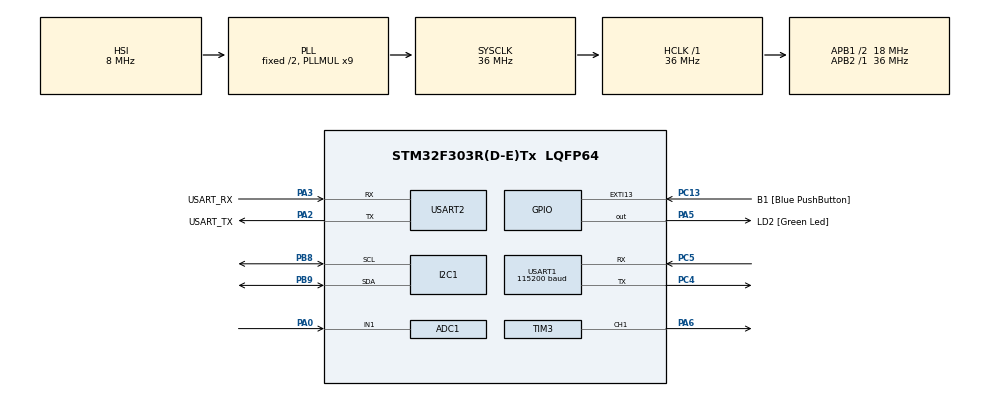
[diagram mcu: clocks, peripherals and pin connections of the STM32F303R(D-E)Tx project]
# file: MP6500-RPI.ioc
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ADC1.Channel-0\#ChannelRegularConversion=ADC_CHANNEL_1
ADC1.ContinuousConvMode=ENABLE
ADC1.DMAContinuousRequests=ENABLE
ADC1.NbrOfConversion=1
ADC1.NbrOfConversionFlag=1
ADC1.Offset-0\#ChannelRegularConversion=0
ADC1.OffsetNumber-0\#ChannelRegularConversion=ADC_OFFSET_NONE
ADC1.Rank-0\#ChannelRegularConversion=1
ADC1.SamplingTime-0\#ChannelRegularConversion=ADC_SAMPLETIME_61CYCLES_5
ADC1.SamplingTimeOPAMP-0\#ChannelRegularConversion=ADC_SAMPLETIME_19CYCLES_5
ADC1.master=1
Dma.ADC1.0.Direction=DMA_PERIPH_TO_MEMORY
Dma.ADC1.0.Instance=DMA1_Channel1
Dma.ADC1.0.MemDataAlignment=DMA_MDATAALIGN_HALFWORD
Dma.ADC1.0.MemInc=DMA_MINC_ENABLE
Dma.ADC1.0.Mode=DMA_CIRCULAR
Dma.ADC1.0.PeriphDataAlignment=DMA_PDATAALIGN_HALFWORD
Dma.ADC1.0.PeriphInc=DMA_PINC_DISABLE
Dma.ADC1.0.Priority=DMA_PRIORITY_LOW
Dma.Request0=ADC1
FREERTOS.Mutexes01=uartMutex,Dynamic,NULL,Available
FREERTOS.Queues01=sensorDataQueu,16,6,1,Dynamic,NULL,NULL
FREERTOS.Tasks01=defaultTask,24,128,StartDefaultTask,Default,NULL,Dynamic,NULL,NULL;Task_ReadSensor,24,128,StartTask_ReadSensor,Default,NULL,Dynamic,NULL,NULL;TaskSendMAVLINK,24,512,StartTask_SendMAVLINK,Default,NULL,Dynamic,NULL,NULL;Task_Heartbeat,24,512,StartTaskHeartbeat,Default,NULL,Dynamic,NULL,NULL;Task_Servo,24,128,StartTask_Servo,Default,NULL,Dynamic,NULL,NULL
FREERTOS.configTOTAL_HEAP_SIZE=16384
I2C1.Timing=0x00201D2B
Mcu.Family=STM32F3
Mcu.Name=STM32F303R(D-E)Tx
Mcu.Package=LQFP64
NVIC.DMA1_Channel1_IRQn=true\:0\:0\:false\:false\:true\:false\:false\:true\:true
NVIC.PriorityGroup=NVIC_PRIORITYGROUP_4
NVIC.TIM6_DAC_IRQn=true\:15\:0\:false\:false\:true\:false\:false\:true\:true
NVIC.TimeBase=TIM6_DAC_IRQn
NVIC.TimeBaseIP=TIM6
PA0.Mode=IN1-Single-Ended
PA0.Signal=ADC1_IN1
PA13.GPIO_Label=TMS
PA13.Mode=Serial_Wire
PA13.Signal=SYS_JTMS-SWDIO
PA14.GPIO_Label=TCK
PA14.Mode=Serial_Wire
PA14.Signal=SYS_JTCK-SWCLK
PA2.GPIO_Label=USART_TX
PA2.GPIO_Mode=GPIO_MODE_AF_PP
PA2.GPIO_PuPd=GPIO_NOPULL
PA2.GPIO_Speed=GPIO_SPEED_FREQ_LOW
PA2.Mode=Asynchronous
PA2.Signal=USART2_TX
PA3.GPIO_Label=USART_RX
PA3.GPIO_Mode=GPIO_MODE_AF_PP
PA3.GPIO_PuPd=GPIO_NOPULL
PA3.GPIO_Speed=GPIO_SPEED_FREQ_LOW
PA3.Mode=Asynchronous
PA3.Signal=USART2_RX
PA5.GPIO_Label=LD2 [Green Led]
PA5.GPIO_Mode=GPIO_MODE_OUTPUT_PP
PA5.GPIO_PuPd=GPIO_NOPULL
PA5.GPIO_Speed=GPIO_SPEED_FREQ_LOW
PA5.Signal=GPIO_Output
PA6.Signal=S_TIM3_CH1
PB3.GPIO_Label=SWO
PB3.Signal=SYS_JTDO-TRACESWO
PB8.Mode=I2C
PB8.Signal=I2C1_SCL
PB9.Mode=I2C
PB9.Signal=I2C1_SDA
PC13.GPIO_Label=B1 [Blue PushButton]
PC13.GPIO_ModeDefaultEXTI=GPIO_MODE_IT_FALLING
PC13.Signal=GPXTI13
PC14-OSC32_IN.Mode=LSE-External-Oscillator
PC14-OSC32_IN.Signal=RCC_OSC32_IN
PC15-OSC32_OUT.Mode=LSE-External-Oscillator
PC15-OSC32_OUT.Signal=RCC_OSC32_OUT
PC4.Mode=Asynchronous
PC4.Signal=USART1_TX
PC5.Mode=Asynchronous
PC5.Signal=USART1_RX
PF0-OSC_IN.Mode=HSE-External-Clock-Source
PF0-OSC_IN.Signal=RCC_OSC_IN
PF1-OSC_OUT.Signal=RCC_OSC_OUT
ProjectManager.HeapSize=0x200
ProjectManager.StackSize=0x400
ProjectManager.TargetToolchain=STM32CubeIDE
RCC.AHBFreq_Value=36000000
RCC.APB1CLKDivider=RCC_HCLK_DIV2
RCC.APB1Freq_Value=18000000
RCC.APB1TimFreq_Value=36000000
RCC.APB2Freq_Value=36000000
RCC.APB2TimFreq_Value=36000000
RCC.CortexFreq_Value=36000000
RCC.HCLKFreq_Value=36000000
RCC.HSE_VALUE=8000000
RCC.HSI_VALUE=8000000
RCC.PLLM=8
RCC.PLLMUL=RCC_PLL_MUL9
RCC.PLLN=336
RCC.PLLP=RCC_PLLP_DIV4
RCC.PLLQ=7
RCC.RCC_PLLsource_Clock_Source_FROM_HSE=RCC_HSE_PREDIV_DIV2
RCC.SYSCLKFreq_VALUE=36000000
RCC.SYSCLKSourceVirtual=RCC_SYSCLKSOURCE_PLLCLK
RCC.USBFreq_Value=36000000
SH.S_TIM3_CH1.0=TIM3_CH1,PWM Generation1 CH1
TIM3.Channel-PWM\ Generation1\ CH1=TIM_CHANNEL_1
TIM3.Period=19999
TIM3.Prescaler=35
TIM3.Pulse-PWM\ Generation1\ CH1=1500
USART1.BaudRate=115200
USART1.VirtualMode-Asynchronous=VM_ASYNC
USART2.VirtualMode-Asynchronous=VM_ASYNC
VP_FREERTOS_VS_CMSIS_V2.Mode=CMSIS_V2
VP_SYS_VS_tim6.Mode=TIM6
board=NUCLEO-F303RE

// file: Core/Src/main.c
/* USER CODE BEGIN Header */
/**
  ******************************************************************************
  * @file           : main.c
  * @brief          : Main program body
  ******************************************************************************
  * @attention
  *
  * Copyright (c) 2026 STMicroelectronics.
  * All rights reserved.
  *
  * This software is licensed under terms that can be found in the LICENSE file
  * in the root directory of this software component.
  * If no LICENSE file comes with this software, it is provided AS-IS.
  *
  ******************************************************************************
  */
/* USER CODE END Header */
#include "main.h"
#include "cmsis_os.h"

/* USER CODE BEGIN Includes */
#include "servo.h"
#include "mpu6500.h"
#include "tasks.h"
/* USER CODE END Includes */

ADC_HandleTypeDef hadc1;
DMA_HandleTypeDef hdma_adc1;

I2C_HandleTypeDef hi2c1;

TIM_HandleTypeDef htim3;

UART_HandleTypeDef huart1;
UART_HandleTypeDef huart2;

/* Definitions for defaultTask */
osThreadId_t defaultTaskHandle;
const osThreadAttr_t defaultTask_attributes = {
  .name = "defaultTask",
  .stack_size = 128 * 4,
  .priority = (osPriority_t) osPriorityNormal,
};
/* Definitions for Task_ReadSensor */
osThreadId_t Task_ReadSensorHandle;
const osThreadAttr_t Task_ReadSensor_attributes = {
  .name = "Task_ReadSensor",
  .stack_size = 128 * 4,
  .priority = (osPriority_t) osPriorityNormal,
};
/* Definitions for TaskSendMAVLINK */
osThreadId_t TaskSendMAVLINKHandle;
const osThreadAttr_t TaskSendMAVLINK_attributes = {
  .name = "TaskSendMAVLINK",
  .stack_size = 512 * 4,
  .priority = (osPriority_t) osPriorityNormal,
};
/* Definitions for Task_Heartbeat */
osThreadId_t Task_HeartbeatHandle;
const osThreadAttr_t Task_Heartbeat_attributes = {
  .name = "Task_Heartbeat",
  .stack_size = 512 * 4,
  .priority = (osPriority_t) osPriorityNormal,
};
/* Definitions for Task_Servo */
osThreadId_t Task_ServoHandle;
const osThreadAttr_t Task_Servo_attributes = {
  .name = "Task_Servo",
  .stack_size = 128 * 4,
  .priority = (osPriority_t) osPriorityNormal,
};
/* Definitions for sensorDataQueu */
osMessageQueueId_t sensorDataQueuHandle;
const osMessageQueueAttr_t sensorDataQueu_attributes = {
  .name = "sensorDataQueu"
};
/* Definitions for uartMutex */
osMutexId_t uartMutexHandle;
const osMutexAttr_t uartMutex_attributes = {
  .name = "uartMutex"
};
/* USER CODE BEGIN PV */
volatile uint16_t adc_raw;
/* USER CODE END PV */

void SystemClock_Config(void);
static void MX_GPIO_Init(void);
static void MX_DMA_Init(void);
static void MX_USART2_UART_Init(void);
static void MX_I2C1_Init(void);
static void MX_USART1_UART_Init(void);
static void MX_TIM3_Init(void);
static void MX_ADC1_Init(void);
void StartDefaultTask(void *argument);
void StartTask_ReadSensor(void *argument);
void StartTask_SendMAVLINK(void *argument);
void StartTaskHeartbeat(void *argument);
void StartTask_Servo(void *argument);

int main(void)
{

  /* MCU Configuration--------------------------------------------------------*/

  /* Reset of all peripherals, Initializes the Flash interface and the Systick. */
  HAL_Init();

  /* Configure the system clock */
  SystemClock_Config();

  /* Initialize all configured peripherals */
  MX_GPIO_Init();
  MX_DMA_Init();
  MX_USART2_UART_Init();
  MX_I2C1_Init();
  MX_USART1_UART_Init();
  MX_TIM3_Init();
  MX_ADC1_Init();
  /* USER CODE BEGIN 2 */
  if (MPU6500_Init() != 0) { Error_Handler(); }
  Servo_init();
  HAL_ADCEx_Calibration_Start(&hadc1, ADC_SINGLE_ENDED);
  HAL_ADC_Start_DMA(&hadc1, (uint32_t*)&adc_raw, 1);
  HAL_NVIC_DisableIRQ(DMA1_Channel1_IRQn);
  /* USER CODE END 2 */

  /* Init scheduler */
  osKernelInitialize();
  /* Create the mutex(es) */
  /* creation of uartMutex */
  uartMutexHandle = osMutexNew(&uartMutex_attributes);

  /* Create the queue(s) */
  /* creation of sensorDataQueu */
  sensorDataQueuHandle = osMessageQueueNew (16, 6, &sensorDataQueu_attributes);

  /* Create the thread(s) */
  /* creation of defaultTask */
  defaultTaskHandle = osThreadNew(StartDefaultTask, NULL, &defaultTask_attributes);

  /* creation of Task_ReadSensor */
  Task_ReadSensorHandle = osThreadNew(StartTask_ReadSensor, NULL, &Task_ReadSensor_attributes);

  /* creation of TaskSendMAVLINK */
  TaskSendMAVLINKHandle = osThreadNew(StartTask_SendMAVLINK, NULL, &TaskSendMAVLINK_attributes);

  /* creation of Task_Heartbeat */
  Task_HeartbeatHandle = osThreadNew(StartTaskHeartbeat, NULL, &Task_Heartbeat_attributes);

  /* creation of Task_Servo */
  Task_ServoHandle = osThreadNew(StartTask_Servo, NULL, &Task_Servo_attributes);

  /* Start scheduler */
  osKernelStart();

  /* We should never get here as control is now taken by the scheduler */

  /* Infinite loop */
  while (1)
  {

  }
}

void SystemClock_Config(void)
{
  RCC_OscInitTypeDef RCC_OscInitStruct = {0};
  RCC_ClkInitTypeDef RCC_ClkInitStruct = {0};
  RCC_PeriphCLKInitTypeDef PeriphClkInit = {0};

  /** Initializes the RCC Oscillators according to the specified parameters
  * in the RCC_OscInitTypeDef structure.
  */
  RCC_OscInitStruct.OscillatorType = RCC_OSCILLATORTYPE_HSI;
  RCC_OscInitStruct.HSIState = RCC_HSI_ON;
  RCC_OscInitStruct.HSICalibrationValue = RCC_HSICALIBRATION_DEFAULT;
  RCC_OscInitStruct.PLL.PLLState = RCC_PLL_ON;
  RCC_OscInitStruct.PLL.PLLSource = RCC_PLLSOURCE_HSI;
  RCC_OscInitStruct.PLL.PLLMUL = RCC_PLL_MUL9;
  RCC_OscInitStruct.PLL.PREDIV = RCC_PREDIV_DIV1;
  if (HAL_RCC_OscConfig(&RCC_OscInitStruct) != HAL_OK)
  {
    Error_Handler();
  }

  /** Initializes the CPU, AHB and APB buses clocks
  */
  RCC_ClkInitStruct.ClockType = RCC_CLOCKTYPE_HCLK|RCC_CLOCKTYPE_SYSCLK
                              |RCC_CLOCKTYPE_PCLK1|RCC_CLOCKTYPE_PCLK2;
  RCC_ClkInitStruct.SYSCLKSource = RCC_SYSCLKSOURCE_PLLCLK;
  RCC_ClkInitStruct.AHBCLKDivider = RCC_SYSCLK_DIV1;
  RCC_ClkInitStruct.APB1CLKDivider = RCC_HCLK_DIV2;
  RCC_ClkInitStruct.APB2CLKDivider = RCC_HCLK_DIV1;

  if (HAL_RCC_ClockConfig(&RCC_ClkInitStruct, FLASH_LATENCY_1) != HAL_OK)
  {
    Error_Handler();
  }
  PeriphClkInit.PeriphClockSelection = RCC_PERIPHCLK_USART1|RCC_PERIPHCLK_USART2
                              |RCC_PERIPHCLK_I2C1|RCC_PERIPHCLK_ADC12
                              |RCC_PERIPHCLK_TIM34;
  PeriphClkInit.Usart1ClockSelection = RCC_USART1CLKSOURCE_PCLK2;
  PeriphClkInit.Usart2ClockSelection = RCC_USART2CLKSOURCE_PCLK1;
  PeriphClkInit.Adc12ClockSelection = RCC_ADC12PLLCLK_DIV1;
  PeriphClkInit.I2c1ClockSelection = RCC_I2C1CLKSOURCE_HSI;
  PeriphClkInit.Tim34ClockSelection = RCC_TIM34CLK_HCLK;
  if (HAL_RCCEx_PeriphCLKConfig(&PeriphClkInit) != HAL_OK)
  {
    Error_Handler();
  }
}

static void MX_ADC1_Init(void)
{

  ADC_MultiModeTypeDef multimode = {0};
  ADC_ChannelConfTypeDef sConfig = {0};

  /** Common config
  */
  hadc1.Instance = ADC1;
  hadc1.Init.ClockPrescaler = ADC_CLOCK_ASYNC_DIV1;
  hadc1.Init.Resolution = ADC_RESOLUTION_12B;
  hadc1.Init.ScanConvMode = ADC_SCAN_DISABLE;
  hadc1.Init.ContinuousConvMode = ENABLE;
  hadc1.Init.DiscontinuousConvMode = DISABLE;
  hadc1.Init.ExternalTrigConvEdge = ADC_EXTERNALTRIGCONVEDGE_NONE;
  hadc1.Init.ExternalTrigConv = ADC_SOFTWARE_START;
  hadc1.Init.DataAlign = ADC_DATAALIGN_RIGHT;
  hadc1.Init.NbrOfConversion = 1;
  hadc1.Init.DMAContinuousRequests = ENABLE;
  hadc1.Init.EOCSelection = ADC_EOC_SINGLE_CONV;
  hadc1.Init.LowPowerAutoWait = DISABLE;
  hadc1.Init.Overrun = ADC_OVR_DATA_OVERWRITTEN;
  if (HAL_ADC_Init(&hadc1) != HAL_OK)
  {
    Error_Handler();
  }

  /** Configure the ADC multi-mode
  */
  multimode.Mode = ADC_MODE_INDEPENDENT;
  if (HAL_ADCEx_MultiModeConfigChannel(&hadc1, &multimode) != HAL_OK)
  {
    Error_Handler();
  }

  /** Configure Regular Channel
  */
  sConfig.Channel = ADC_CHANNEL_1;
  sConfig.Rank = ADC_REGULAR_RANK_1;
  sConfig.SingleDiff = ADC_SINGLE_ENDED;
  sConfig.SamplingTime = ADC_SAMPLETIME_61CYCLES_5;
  sConfig.OffsetNumber = ADC_OFFSET_NONE;
  sConfig.Offset = 0;
  if (HAL_ADC_ConfigChannel(&hadc1, &sConfig) != HAL_OK)
  {
    Error_Handler();
  }

}

static void MX_I2C1_Init(void)
{

  hi2c1.Instance = I2C1;
  hi2c1.Init.Timing = 0x00201D2B;
  hi2c1.Init.OwnAddress1 = 0;
  hi2c1.Init.AddressingMode = I2C_ADDRESSINGMODE_7BIT;
  hi2c1.Init.DualAddressMode = I2C_DUALADDRESS_DISABLE;
  hi2c1.Init.OwnAddress2 = 0;
  hi2c1.Init.OwnAddress2Masks = I2C_OA2_NOMASK;
  hi2c1.Init.GeneralCallMode = I2C_GENERALCALL_DISABLE;
  hi2c1.Init.NoStretchMode = I2C_NOSTRETCH_DISABLE;
  if (HAL_I2C_Init(&hi2c1) != HAL_OK)
  {
    Error_Handler();
  }

  /** Configure Analogue filter
  */
  if (HAL_I2CEx_ConfigAnalogFilter(&hi2c1, I2C_ANALOGFILTER_ENABLE) != HAL_OK)
  {
    Error_Handler();
  }

  /** Configure Digital filter
  */
  if (HAL_I2CEx_ConfigDigitalFilter(&hi2c1, 0) != HAL_OK)
  {
    Error_Handler();
  }

}

static void MX_TIM3_Init(void)
{

  TIM_MasterConfigTypeDef sMasterConfig = {0};
  TIM_OC_InitTypeDef sConfigOC = {0};

  htim3.Instance = TIM3;
  htim3.Init.Prescaler = 35;
  htim3.Init.CounterMode = TIM_COUNTERMODE_UP;
  htim3.Init.Period = 19999;
  htim3.Init.ClockDivision = TIM_CLOCKDIVISION_DIV1;
  htim3.Init.AutoReloadPreload = TIM_AUTORELOAD_PRELOAD_DISABLE;
  if (HAL_TIM_PWM_Init(&htim3) != HAL_OK)
  {
    Error_Handler();
  }
  sMasterConfig.MasterOutputTrigger = TIM_TRGO_RESET;
  sMasterConfig.MasterSlaveMode = TIM_MASTERSLAVEMODE_DISABLE;
  if (HAL_TIMEx_MasterConfigSynchronization(&htim3, &sMasterConfig) != HAL_OK)
  {
    Error_Handler();
  }
  sConfigOC.OCMode = TIM_OCMODE_PWM1;
  sConfigOC.Pulse = 1500;
  sConfigOC.OCPolarity = TIM_OCPOLARITY_HIGH;
  sConfigOC.OCFastMode = TIM_OCFAST_DISABLE;
  if (HAL_TIM_PWM_ConfigChannel(&htim3, &sConfigOC, TIM_CHANNEL_1) != HAL_OK)
  {
    Error_Handler();
  }
  HAL_TIM_MspPostInit(&htim3);

}

static void MX_USART1_UART_Init(void)
{

  huart1.Instance = USART1;
  huart1.Init.BaudRate = 115200;
  huart1.Init.WordLength = UART_WORDLENGTH_8B;
  huart1.Init.StopBits = UART_STOPBITS_1;
  huart1.Init.Parity = UART_PARITY_NONE;
  huart1.Init.Mode = UART_MODE_TX_RX;
  huart1.Init.HwFlowCtl = UART_HWCONTROL_NONE;
  huart1.Init.OverSampling = UART_OVERSAMPLING_16;
  huart1.Init.OneBitSampling = UART_ONE_BIT_SAMPLE_DISABLE;
  huart1.AdvancedInit.AdvFeatureInit = UART_ADVFEATURE_NO_INIT;
  if (HAL_UART_Init(&huart1) != HAL_OK)
  {
    Error_Handler();
  }

}

static void MX_USART2_UART_Init(void)
{

  huart2.Instance = USART2;
  huart2.Init.BaudRate = 38400;
  huart2.Init.WordLength = UART_WORDLENGTH_8B;
  huart2.Init.StopBits = UART_STOPBITS_1;
  huart2.Init.Parity = UART_PARITY_NONE;
  huart2.Init.Mode = UART_MODE_TX_RX;
  huart2.Init.HwFlowCtl = UART_HWCONTROL_NONE;
  huart2.Init.OverSampling = UART_OVERSAMPLING_16;
  huart2.Init.OneBitSampling = UART_ONE_BIT_SAMPLE_DISABLE;
  huart2.AdvancedInit.AdvFeatureInit = UART_ADVFEATURE_NO_INIT;
  if (HAL_UART_Init(&huart2) != HAL_OK)
  {
    Error_Handler();
  }

}

static void MX_DMA_Init(void)
{

  /* DMA controller clock enable */
  __HAL_RCC_DMA1_CLK_ENABLE();

  /* DMA interrupt init */
  /* DMA1_Channel1_IRQn interrupt configuration */
  HAL_NVIC_SetPriority(DMA1_Channel1_IRQn, 0, 0);
  HAL_NVIC_EnableIRQ(DMA1_Channel1_IRQn);

}

static void MX_GPIO_Init(void)
{
  GPIO_InitTypeDef GPIO_InitStruct = {0};

  /* GPIO Ports Clock Enable */
  __HAL_RCC_GPIOC_CLK_ENABLE();
  __HAL_RCC_GPIOF_CLK_ENABLE();
  __HAL_RCC_GPIOA_CLK_ENABLE();
  __HAL_RCC_GPIOB_CLK_ENABLE();

  /*Configure GPIO pin Output Level */
  HAL_GPIO_WritePin(LD2_GPIO_Port, LD2_Pin, GPIO_PIN_RESET);

  /*Configure GPIO pin : B1_Pin */
  GPIO_InitStruct.Pin = B1_Pin;
  GPIO_InitStruct.Mode = GPIO_MODE_IT_FALLING;
  GPIO_InitStruct.Pull = GPIO_NOPULL;
  HAL_GPIO_Init(B1_GPIO_Port, &GPIO_InitStruct);

  /*Configure GPIO pin : LD2_Pin */
  GPIO_InitStruct.Pin = LD2_Pin;
  GPIO_InitStruct.Mode = GPIO_MODE_OUTPUT_PP;
  GPIO_InitStruct.Pull = GPIO_NOPULL;
  GPIO_InitStruct.Speed = GPIO_SPEED_FREQ_LOW;
  HAL_GPIO_Init(LD2_GPIO_Port, &GPIO_InitStruct);

}

void StartDefaultTask(void *argument)
{
  for(;;)
  {
    osDelay(1);
  }
}

void HAL_TIM_PeriodElapsedCallback(TIM_HandleTypeDef *htim)
{
  if (htim->Instance == TIM6)
  {
    HAL_IncTick();
  }
}

void Error_Handler(void)
{
  __disable_irq();
  while (1)
  {
  }
}
